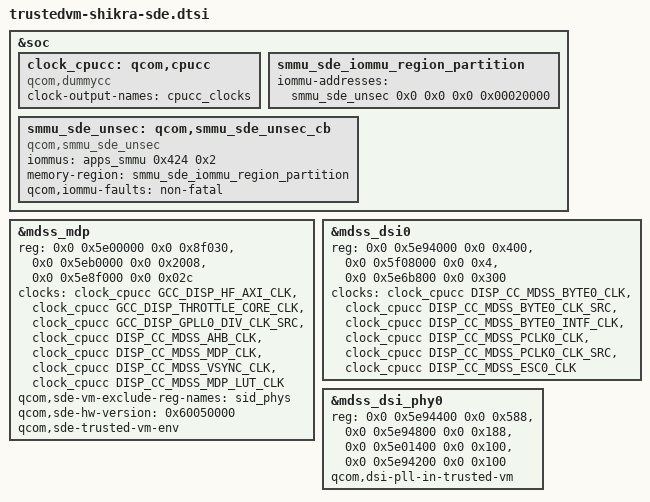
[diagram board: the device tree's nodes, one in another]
// SPDX-License-Identifier: BSD-3-Clause
/*
 * Copyright (c) Qualcomm Technologies, Inc. and/or its subsidiaries.
 */

#include <dt-bindings/clock/qcom,shikra-gcc.h>
#include <dt-bindings/clock/qcom,shikra-dispcc.h>
#include <dt-bindings/interconnect/qcom,shikra.h>

#include "shikra-sde-common.dtsi"
#include  "trustedvm-shikra-avf-required-subnodes.dtsi"

&soc {
	/* dummy display clock provider */
	clock_cpucc: qcom,cpucc {
		compatible = "qcom,dummycc";
		clock-output-names = "cpucc_clocks";
		#clock-cells = <1>;
	};

	smmu_sde_iommu_region_partition: smmu_sde_iommu_region_partition {
		iommu-addresses = <&smmu_sde_unsec 0x0 0x0 0x0 0x00020000>;
	};

	smmu_sde_unsec: qcom,smmu_sde_unsec_cb {
		compatible = "qcom,smmu_sde_unsec";
		iommus = <&apps_smmu 0x424 0x2>;
		memory-region = <&smmu_sde_iommu_region_partition>;
		qcom,iommu-faults = "non-fatal";
	};
};

&mdss_mdp {
		reg = <0x0 0x5e00000 0x0 0x8f030>,
			<0x0 0x5eb0000 0x0 0x2008>,
			<0x0 0x5e8f000 0x0 0x02c>;
		reg-names = "mdp_phys",
			"vbif_phys",
			"sid_phys";

		clocks =
			<&clock_cpucc GCC_DISP_HF_AXI_CLK>,
			<&clock_cpucc GCC_DISP_THROTTLE_CORE_CLK>,
			<&clock_cpucc GCC_DISP_GPLL0_DIV_CLK_SRC>,
			<&clock_cpucc DISP_CC_MDSS_AHB_CLK>,
			<&clock_cpucc DISP_CC_MDSS_MDP_CLK>,
			<&clock_cpucc DISP_CC_MDSS_VSYNC_CLK>,
			<&clock_cpucc DISP_CC_MDSS_MDP_LUT_CLK>;
		clock-names = "gcc_bus", "throttle_clk", "div_clk",
				"iface_clk", "core_clk", "vsync_clk",
				"lut_clk";

		qcom,sde-vm-exclude-reg-names = "sid_phys";
		qcom,sde-hw-version = <0x60050000>;
		qcom,sde-trusted-vm-env;
};

&mdss_dsi0 {
	reg =   <0x0 0x5e94000 0x0 0x400>,
		<0x0 0x5f08000 0x0 0x4>,
		<0x0 0x5e6b800 0x0 0x300>;
	reg-names = "dsi_ctrl", "disp_cc_base", "mdp_intf_base";

	clocks =
		<&clock_cpucc DISP_CC_MDSS_BYTE0_CLK>,
		<&clock_cpucc DISP_CC_MDSS_BYTE0_CLK_SRC>,
		<&clock_cpucc DISP_CC_MDSS_BYTE0_INTF_CLK>,
		<&clock_cpucc DISP_CC_MDSS_PCLK0_CLK>,
		<&clock_cpucc DISP_CC_MDSS_PCLK0_CLK_SRC>,
		<&clock_cpucc DISP_CC_MDSS_ESC0_CLK>;
	clock-names = "byte_clk", "byte_clk_rcg", "byte_intf_clk",
			"pixel_clk", "pixel_clk_rcg", "esc_clk";
};

&mdss_dsi_phy0 {
	reg = <0x0 0x5e94400 0x0 0x588>,
		<0x0 0x5e94800 0x0 0x188>,
		<0x0 0x5e01400 0x0 0x100>,
		<0x0 0x5e94200 0x0 0x100>;
	reg-names = "dsi_phy", "pll_base", "phy_clamp_base",
		"dyn_refresh_base";

	qcom,dsi-pll-in-trusted-vm;
};
